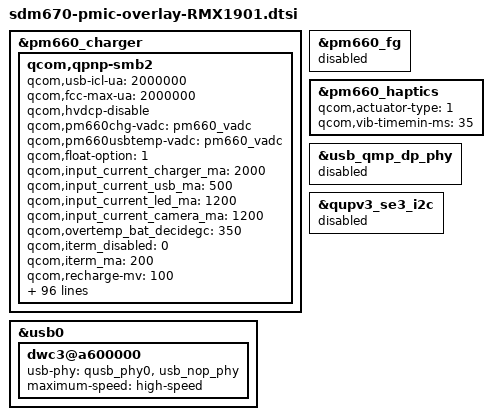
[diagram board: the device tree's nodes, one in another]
&pm660_charger {
    qcom,qpnp-smb2 {
        /delete-property/ qcom,wipower-max-uw;
        /delete-property/ qcom,auto-recharge-soc;
        
        //for smb2:
        qcom,usb-icl-ua = <2000000>;
        qcom,fcc-max-ua = <2000000>;
        //qcom,fv-max-uv = <4373000>;
        qcom,hvdcp-disable;
        qcom,pm660chg-vadc = <&pm660_vadc>;//chargID
        qcom,pm660usbtemp-vadc = <&pm660_vadc>;//usb temp
        //qcom,otg-cl-ua = <2000000>;
        qcom,float-option = <1>;

        //for oppo chg framework:
        qcom,input_current_charger_ma = <2000>;
        qcom,input_current_usb_ma = <500>;

        qcom,input_current_led_ma = <1200>;

        qcom,input_current_camera_ma = <1200>;
        //qcom,input_current_led_ma_overtemp = <900>;
        qcom,overtemp_bat_decidegc = <350>;
        qcom,iterm_disabled = <0>;
        qcom,iterm_ma = <200>;
        qcom,recharge-mv = <100>;
        qcom,batt_capacity_mah = <3765>;

        qcom,removed_bat_decidegc = <190>;  /*<-19C*/

        qcom,cold_bat_decidegc = <20>;  /*-3C~0C*/
        qcom,temp_cold_vfloat_mv = <3980>;
        qcom,temp_cold_fastchg_current_ma = <330>;

        qcom,little_cold_bat_decidegc = <0>;    /*0C~5C*/
        qcom,temp_little_cold_vfloat_mv = <4387>;
        qcom,temp_little_cold_fastchg_current_ma_high = <1788>;
        qcom,temp_little_cold_fastchg_current_ma_low = <1073>;

        qcom,cool_bat_decidegc = <50>;  /*5C~12C*/
        qcom,temp_cool_vfloat_mv = <4387>;
        qcom,temp_cool_fastchg_current_ma_high = <2100>;
        qcom,temp_cool_fastchg_current_ma_low = <1788>;

        qcom,little_cool_bat_decidegc = <120>;  /*12C~16C*/
        qcom,temp_little_cool_vfloat_mv = <4387>;
        qcom,temp_little_cool_fastchg_current_ma = <2100>;

        qcom,normal_bat_decidegc = <160>;   /*16C~45C*/
        qcom,temp_normal_fastchg_current_ma = <2100>;
        qcom,temp_normal_vfloat_mv = <4387>;

        qcom,warm_bat_decidegc = <450>;     /*48C~53C*/ /*8pin Bat Vooc project need add 3 degree C*/
        qcom,temp_warm_vfloat_mv = <4130>;
        qcom,temp_warm_fastchg_current_ma = <1016>;

        qcom,hot_bat_decidegc = <530>;

        qcom,non_standard_vfloat_mv = <3980>;
        qcom,non_standard_fastchg_current_ma = <512>;
        qcom,short_c_bat_cv_mv = <0x10ea>;
        qcom,short_c_bat_vfloat_mv = <0xed8>;
        qcom,short_c_bat_fastchg_current_ma = <0x200>;

        qcom,cold_vfloat_sw_limit = <3930>;
        qcom,little_cold_vfloat_sw_limit = <4350>;
        qcom,cool_vfloat_sw_limit = <4350>;
        qcom,little_cool_vfloat_sw_limit = <4350>;
        qcom,normal_vfloat_sw_limit = <4350>;
        qcom,warm_vfloat_sw_limit = <4080>;
        qcom,non_standard_vfloat_sw_limit = <3930>;
        qcom,short_c_bat_vfloat_sw_limit = <0xea6>;


        qcom,max_chg_time_sec = <36000>;
        qcom,charger_hv_thr = <5800>;
        qcom,charger_lv_thr = <3400>;
        qcom,vbatt_full_thr = <4400>;
        qcom,vbatt_hv_thr = <4500>;
        qcom,vfloat_step_mv = <8>;
        qcom,non_standard_vfloat_over_sw_limit = <3980>;
        qcom,cold_vfloat_over_sw_limit = <3980>;
        qcom,little_cold_vfloat_over_sw_limit = <4387>;
        qcom,cool_vfloat_over_sw_limit = <4387>;
        qcom,little_cool_vfloat_over_sw_limit = <4387>;
        qcom,normal_vfloat_over_sw_limit = <4387>;
        qcom,warm_vfloat_over_sw_limit = <4130>;

        qcom,vbatt_power_off = <3300>;
        qcom,vbatt_soc_1 = <3410>;
        qcom,vooc_project = <1>;
        qcom,vbatt_num = <1>;
            qcom,ffc_support;


        qcom,normal_vterm_hw_inc = <150>;
        qcom,non_normal_vterm_hw_inc = <18>;
        qcom,ff1_normal_fastchg_ma = <0x3e8>;
        qcom,ffc2_normal_fastchg_ma = <0x2ee>;
        qcom,ffc2_temp_warm_decidegc = <0x15e>;
        qcom,ffc2_warm_fastchg_ma = <0x352>;
        qcom,ffc2_temp_high_decidegc = <0x190>;
        qcom,ffc2_temp_low_decidegc = <0x78>;
        qcom,ffc2_exit_step_ma = <0x64>;
        qcom,ffc_normal_vfloat_sw_limit = <0x114e>;
        qcom,ffc_temp_normal_vfloat_mv = <0x1194>;
        qcom,ffc_normal_vfloat_over_sw_limit = <0x1194>;


        qcom,default_iterm_ma = <200>;
        qcom,default_temp_normal_fastchg_current_ma = <2000>;
        qcom,default_normal_vfloat_sw_limit = <4350>;
        qcom,default_temp_normal_vfloat_mv = <4387>;
        qcom,default_normal_vfloat_over_sw_limit = <4397>;

        qcom,default_temp_little_cool_fastchg_current_ma = <2100>;
        qcom,default_little_cool_vfloat_sw_limit = <4350>;
        qcom,default_temp_little_cool_vfloat_mv = <4387>;
        qcom,default_little_cool_vfloat_over_sw_limit = <4397>;
        ///qcom,offset_temp = <30>;
        //for control:
        //qcom,suspend_after_full;
        qcom,check_batt_full_by_sw;
        qcom,external_gauge;
        qcom,chg_ctrl_by_lcd;
        qcom,chg_ctrl_by_camera;
        qcom,sw_vfloat_over_protect_enable;
        qcom,charger_id_num = <7>;

        qcom,chargerid_switch-gpio = <&tlmm 93 0x00>;
        qcom,ship-gpio = <&tlmm 67 0x00>;

        //qcom,dischg-gpio = <&pm660l_gpios 7 0x00>;
        pinctrl-names = "chargerid_switch_active", "chargerid_switch_sleep", "chargerid_switch_default",
                    "ship_active", "ship_sleep", "shortc_active",
                    "chg_qupv3_se12_2uart_sleep", "chg_qupv3_se12_2uart_default";
                    /*"dischg_enable", "dischg_disable",*/
        pinctrl-0 = <&chargerid_switch_active>;
        pinctrl-1 = <&chargerid_switch_sleep>;
        pinctrl-2 = <&chargerid_switch_default>;
        pinctrl-3 = <&ship_active>;
        pinctrl-4 = <&ship_sleep>;
        pinctrl-5 = <&shortc_active>;
        pinctrl-6 = <&chg_qupv3_se12_2uart_sleep>;
        pinctrl-7 = <&chg_qupv3_se12_2uart_default>;
    };
};

&pm660_fg {
        status = "disabled";
};

&pm660_haptics {
        qcom,actuator-type = <1>;
        qcom,vib-timemin-ms = <35>;
};

&usb0 {
    dwc3@a600000 {
        usb-phy = <&qusb_phy0>, <&usb_nop_phy>;
        maximum-speed = "high-speed";
    };
};

&usb_qmp_dp_phy {
    status = "disabled";
};
&qupv3_se3_i2c {
    status = "disabled";
};
